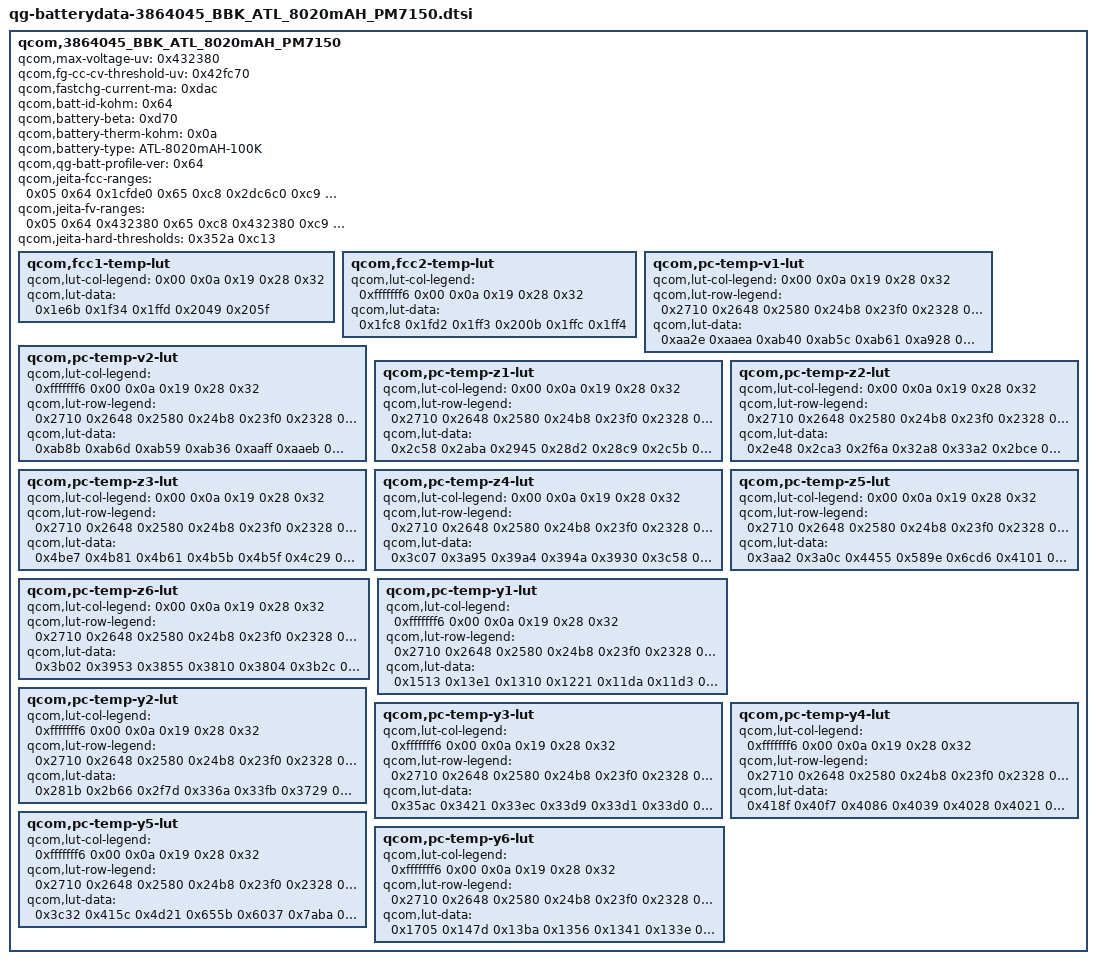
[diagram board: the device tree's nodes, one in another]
 /*
 * Copyright (c) 2026 XiKoTaSu <3329989998@qq.com>
 */			
			
			qcom,3864045_BBK_ATL_8020mAH_PM7150 {
				qcom,max-voltage-uv = <0x432380>;
				qcom,fg-cc-cv-threshold-uv = <0x42fc70>;
				qcom,fastchg-current-ma = <0xdac>;
				qcom,batt-id-kohm = <0x64>;
				qcom,battery-beta = <0xd70>;
				qcom,battery-therm-kohm = <0x0a>;
				qcom,battery-type = "ATL-8020mAH-100K";
				qcom,qg-batt-profile-ver = <0x64>;
				qcom,jeita-fcc-ranges = <0x05 0x64 0x1cfde0 0x65 0xc8 0x2dc6c0 0xc9 0x1c2 0x3567e0 0x1c3 0x221 0x2625a0>;
				qcom,jeita-fv-ranges = <0x05 0x64 0x432380 0x65 0xc8 0x432380 0xc9 0x1c2 0x432380 0x1c3 0x221 0x3e8fa0>;
				qcom,jeita-hard-thresholds = <0x352a 0xc13>;

				qcom,fcc1-temp-lut {
					qcom,lut-col-legend = <0x00 0x0a 0x19 0x28 0x32>;
					qcom,lut-data = <0x1e6b 0x1f34 0x1ffd 0x2049 0x205f>;
				};

				qcom,fcc2-temp-lut {
					qcom,lut-col-legend = <0xfffffff6 0x00 0x0a 0x19 0x28 0x32>;
					qcom,lut-data = <0x1fc8 0x1fd2 0x1ff3 0x200b 0x1ffc 0x1ff4>;
				};

				qcom,pc-temp-v1-lut {
					qcom,lut-col-legend = <0x00 0x0a 0x19 0x28 0x32>;
					qcom,lut-row-legend = <0x2710 0x2648 0x2580 0x24b8 0x23f0 0x2328 0x2260 0x2198 0x20d0 0x2008 0x1f40 0x1e78 0x1db0 0x1ce8 0x1c20 0x1b58 0x1a90 0x19c8 0x1900 0x1838 0x1770 0x16a8 0x15e0 0x1518 0x1450 0x1388 0x12c0 0x11f8 0x1130 0x1068 0xfa0 0xed8 0xe10 0xd48 0xc80 0xbb8 0xaf0 0xa28 0x960 0x898 0x7d0 0x708 0x640 0x578 0x4b0 0x3e8 0x384 0x320 0x2bc 0x258 0x1f4 0x190 0x12c 0xc8 0x64 0x00>;
					qcom,lut-data = <0xaa2e 0xaaea 0xab40 0xab5c 0xab61 0xa928 0xa9f7 0xaa82 0xaa9c 0xaa9e 0xa832 0xa907 0xa9a4 0xa9d1 0xa9d6 0xa748 0xa818 0xa8b7 0xa8f1 0xa8ff 0xa662 0xa72c 0xa7ca 0xa80a 0xa820 0xa580 0xa641 0xa6db 0xa71f 0xa739 0xa4a2 0xa55a 0xa5ed 0xa631 0xa64d 0xa3cb 0xa477 0xa502 0xa545 0xa561 0xa2fa 0xa39a 0xa41a 0xa45c 0xa476 0xa231 0xa2c2 0xa335 0xa374 0xa38c 0xa17b 0xa1f2 0xa253 0xa28d 0xa2a5 0xa0c7 0xa134 0xa17a 0xa1aa 0xa1c1 0x9ff3 0xa07b 0xa0b3 0xa0cf 0xa0e3 0x9ef6 0x9faa 0x9ff1 0x9ffd 0xa00c 0x9dfb 0x9ebc 0x9f15 0x9f2c 0x9f3a 0x9d0f 0x9dd2 0x9e20 0x9e5b 0x9e6d 0x9c31 0x9cec 0x9d46 0x9d92 0x9da8 0x9b8b 0x9c1b 0x9c95 0x9cdd 0x9cf1 0x9b11 0x9b80 0x9bf2 0x9c30 0x9c43 0x9aa1 0x9b10 0x9b4d 0x9b79 0x9b8c 0x9a27 0x9a8f 0x9aaa 0x9ab8 0x9acb 0x99ad 0x99cb 0x99ed 0x99f2 0x9a04 0x992f 0x98ec 0x98f3 0x991b 0x992f 0x98ae 0x9831 0x9814 0x984d 0x985d 0x982d 0x9784 0x9792 0x97b2 0x97be 0x97ae 0x9701 0x9731 0x9738 0x9741 0x972e 0x96ad 0x96d0 0x96c9 0x96cf 0x96be 0x966d 0x966e 0x9662 0x9664 0x965c 0x9632 0x9615 0x9605 0x9601 0x9607 0x95fd 0x95ca 0x95ae 0x95a7 0x95ce 0x95cc 0x9587 0x955f 0x9555 0x95a6 0x959e 0x954c 0x9519 0x950b 0x9584 0x9573 0x9519 0x94dc 0x94c9 0x9567 0x954b 0x94e9 0x94a4 0x948b 0x954d 0x9526 0x94c0 0x9474 0x9452 0x952f 0x9500 0x9498 0x9447 0x941c 0x950f 0x94da 0x946f 0x9414 0x93de 0x94e8 0x94b0 0x9445 0x93da 0x939a 0x94ae 0x9470 0x940d 0x9395 0x934d 0x945d 0x940e 0x93b1 0x9340 0x92f7 0x93fb 0x939e 0x9340 0x92dc 0x9294 0x937e 0x932a 0x92cb 0x926a 0x9224 0x92f0 0x92a6 0x9248 0x91e6 0x91a0 0x9251 0x9208 0x91ad 0x914e 0x910e 0x91cf 0x9181 0x9125 0x90c9 0x908b 0x9178 0x9131 0x90d3 0x907c 0x903d 0x915c 0x9112 0x90be 0x9065 0x9029 0x913e 0x90fe 0x90ac 0x9057 0x901b 0x9122 0x90e6 0x9098 0x9045 0x9008 0x90e3 0x90ab 0x9056 0x8ff2 0x8fa6 0x8fd6 0x8f94 0x8f3b 0x8eca 0x8e76 0x8e1a 0x8de0 0x8d89 0x8d13 0x8cbd 0x8be4 0x8baa 0x8b54 0x8ada 0x8a83 0x88e5 0x88a6 0x8850 0x87d1 0x877d 0x842e 0x83f2 0x83a6 0x8323 0x82d3 0x7530 0x7530 0x7530 0x7530 0x7530>;
				};

				qcom,pc-temp-v2-lut {
					qcom,lut-col-legend = <0xfffffff6 0x00 0x0a 0x19 0x28 0x32>;
					qcom,lut-row-legend = <0x2710 0x2648 0x2580 0x24b8 0x23f0 0x2328 0x2260 0x2198 0x20d0 0x2008 0x1f40 0x1e78 0x1db0 0x1ce8 0x1c20 0x1b58 0x1a90 0x19c8 0x1900 0x1838 0x1770 0x16a8 0x15e0 0x1518 0x1450 0x1388 0x12c0 0x11f8 0x1130 0x1068 0xfa0 0xed8 0xe10 0xd48 0xc80 0xbb8 0xaf0 0xa28 0x960 0x898 0x7d0 0x708 0x640 0x578 0x4b0 0x3e8 0x384 0x320 0x2bc 0x258 0x1f4 0x190 0x12c 0xc8 0x64 0x00>;
					qcom,lut-data = <0xab8b 0xab6d 0xab59 0xab36 0xaaff 0xaaeb 0xaa06 0xaa27 0xaa48 0xaa3e 0xaa12 0xaa04 0xa89c 0xa8f5 0xa93f 0xa94a 0xa926 0xa91c 0xa74d 0xa7da 0xa840 0xa858 0xa83a 0xa833 0xa613 0xa6d5 0xa749 0xa769 0xa74e 0xa749 0xa500 0xa5d6 0xa656 0xa67a 0xa662 0xa65f 0xa422 0xa4d8 0xa566 0xa58d 0xa576 0xa574 0xa351 0xa3e2 0xa479 0xa4a1 0xa48a 0xa488 0xa250 0xa2f4 0xa393 0xa3ba 0xa3a3 0xa3a1 0xa126 0xa20e 0xa2b3 0xa2d6 0xa2bd 0xa2bb 0xa059 0xa13c 0xa1d5 0xa1f3 0xa1db 0xa1d9 0x9fff 0xa08e 0xa0f8 0xa10e 0xa0fb 0xa0fb 0x9fa1 0x9fdc 0xa023 0xa034 0xa021 0xa021 0x9e6b 0x9ef9 0x9f6e 0x9f7a 0x9f54 0x9f4f 0x9c0e 0x9dec 0x9ec8 0x9ece 0x9e8d 0x9e82 0x9a8c 0x9cd6 0x9df0 0x9dfe 0x9dc5 0x9dbc 0x99e3 0x9ba9 0x9cb6 0x9cec 0x9cf7 0x9cfc 0x9956 0x9a95 0x9b87 0x9bf5 0x9c31 0x9c42 0x98aa 0x99cd 0x9aaf 0x9b54 0x9b83 0x9b91 0x97f6 0x9926 0x99f7 0x9ac8 0x9adb 0x9ae2 0x9749 0x987d 0x9941 0x9a09 0x9a0f 0x9a13 0x969a 0x97cd 0x988b 0x9906 0x990c 0x9912 0x9607 0x972b 0x97e6 0x9826 0x982c 0x9833 0x95a2 0x969d 0x9755 0x9788 0x9790 0x9797 0x9553 0x961d 0x96d1 0x9702 0x970e 0x9716 0x950f 0x95a3 0x965a 0x968a 0x9697 0x969e 0x94d6 0x952c 0x95ee 0x961f 0x962b 0x9630 0x94a3 0x94cd 0x958a 0x95bd 0x95c8 0x95cc 0x9474 0x948b 0x952f 0x9563 0x956c 0x956e 0x9449 0x9457 0x94da 0x9510 0x9517 0x9517 0x941e 0x9428 0x948b 0x94c4 0x94cb 0x94c9 0x93f3 0x93fe 0x9440 0x947c 0x9484 0x9481 0x93c7 0x93d5 0x9400 0x9436 0x9440 0x943c 0x9398 0x93af 0x93c9 0x93f4 0x9403 0x93fe 0x9368 0x9388 0x9398 0x93b2 0x93c2 0x93bb 0x9334 0x935b 0x9369 0x936c 0x9367 0x9355 0x92fc 0x9329 0x933c 0x9326 0x92fb 0x92d2 0x92be 0x92f0 0x9308 0x92df 0x929b 0x9264 0x9275 0x92ac 0x92cd 0x9299 0x9247 0x920b 0x9226 0x925e 0x9289 0x924f 0x91f6 0x91b8 0x91d1 0x9204 0x9239 0x9200 0x91a7 0x9167 0x9174 0x919c 0x91d9 0x91a7 0x9153 0x9111 0x911c 0x912b 0x9166 0x913b 0x90e9 0x90a7 0x90c5 0x90b9 0x90dc 0x90b0 0x9061 0x901f 0x9074 0x904d 0x9066 0x9037 0x8ff2 0x8fb8 0x901c 0x8fe5 0x901e 0x9016 0x8fda 0x8fa1 0x8fe9 0x8fb2 0x9009 0x9007 0x8fcb 0x8f93 0x8fb5 0x8f78 0x8ff0 0x8ff1 0x8fb5 0x8f7d 0x8f6b 0x8f32 0x8fc3 0x8fc9 0x8f8b 0x8f4f 0x8eef 0x8ec5 0x8f57 0x8f5b 0x8f0f 0x8ebd 0x8e02 0x8de4 0x8e4d 0x8e1c 0x8daf 0x8d52 0x8c89 0x8c62 0x8c7a 0x8c2b 0x8bc0 0x8b61 0x8a58 0x8a31 0x8a04 0x89b2 0x893c 0x88da 0x872f 0x8706 0x86ad 0x863b 0x85b1 0x853d 0x81f5 0x81e8 0x8178 0x80af 0x801d 0x7fa1 0x719c 0x7000 0x6ede 0x6f3b 0x6fc7 0x7099>;
				};

				qcom,pc-temp-z1-lut {
					qcom,lut-col-legend = <0x00 0x0a 0x19 0x28 0x32>;
					qcom,lut-row-legend = <0x2710 0x2648 0x2580 0x24b8 0x23f0 0x2328 0x2260 0x2198 0x20d0 0x2008 0x1f40 0x1e78 0x1db0 0x1ce8 0x1c20 0x1b58 0x1a90 0x19c8 0x1900 0x1838 0x1770 0x16a8 0x15e0 0x1518 0x1450 0x1388 0x12c0 0x11f8 0x1130 0x1068 0xfa0 0xed8 0xe10 0xd48 0xc80 0xbb8 0xaf0 0xa28 0x960 0x898 0x7d0 0x708 0x640 0x578 0x4b0 0x3e8 0x384 0x320 0x2bc 0x258 0x1f4 0x190 0x12c 0xc8 0x64 0x00>;
					qcom,lut-data = <0x2c58 0x2aba 0x2945 0x28d2 0x28c9 0x2c5b 0x2abf 0x2950 0x28de 0x28d9 0x2c5d 0x2ac0 0x294f 0x28e0 0x28db 0x2c60 0x2abe 0x2949 0x28e0 0x28dd 0x2c60 0x2ab5 0x2945 0x28e1 0x28e0 0x2c5e 0x2aab 0x2942 0x28e3 0x28e4 0x2c5b 0x2aa6 0x2940 0x28e6 0x28e9 0x2c54 0x2aa2 0x2940 0x28e7 0x28ea 0x2c41 0x2a9d 0x2940 0x28e8 0x28e9 0x2c35 0x2a95 0x2940 0x28e8 0x28e9 0x2c35 0x2a90 0x293e 0x28e7 0x28e9 0x2c36 0x2a93 0x293e 0x28e6 0x28e9 0x2c33 0x2a97 0x293f 0x28e6 0x28e9 0x2c2a 0x2a95 0x2940 0x28e6 0x28e9 0x2c21 0x2a85 0x293e 0x28e6 0x28e9 0x2c18 0x2a7b 0x2939 0x28e6 0x28ea 0x2c0f 0x2a7e 0x2937 0x28e6 0x28ea 0x2c0e 0x2a84 0x2939 0x28e6 0x28ea 0x2c1b 0x2a86 0x293c 0x28e7 0x28eb 0x2c28 0x2a89 0x293e 0x28e8 0x28eb 0x2c2a 0x2a8b 0x2941 0x28e9 0x28ec 0x2c27 0x2a8d 0x2943 0x28ea 0x28ed 0x2c28 0x2a8f 0x2946 0x28eb 0x28ee 0x2c2e 0x2a92 0x2948 0x28ed 0x28ef 0x2c33 0x2a95 0x294a 0x28ee 0x28f0 0x2c36 0x2a99 0x294c 0x28ef 0x28f1 0x2c3b 0x2a9e 0x294e 0x28f1 0x28f2 0x2c3f 0x2aa3 0x2951 0x28f2 0x28f3 0x2c42 0x2aa6 0x2954 0x28f4 0x28f4 0x2c46 0x2aa7 0x2956 0x28f5 0x28f5 0x2c47 0x2aa9 0x2959 0x28f7 0x28f6 0x2c4b 0x2aad 0x295b 0x28f8 0x28f7 0x2c50 0x2ab5 0x295d 0x28fa 0x28f8 0x2c54 0x2aba 0x295e 0x28fc 0x28f9 0x2c58 0x2abe 0x2961 0x28fd 0x28fa 0x2c5b 0x2ac0 0x2964 0x28fe 0x28fb 0x2c5d 0x2ac3 0x2966 0x28ff 0x28fc 0x2c5f 0x2ac7 0x2969 0x2901 0x28fe 0x2c62 0x2acd 0x296b 0x2902 0x28ff 0x2c68 0x2ad8 0x296f 0x2904 0x2900 0x2c6f 0x2adf 0x2973 0x2905 0x2902 0x2c82 0x2adb 0x2975 0x2907 0x2903 0x2c8c 0x2ad7 0x2977 0x2909 0x2904 0x2c8a 0x2add 0x297b 0x290a 0x2905 0x2c93 0x2ae1 0x297f 0x290c 0x2906 0x2c7a 0x2ae3 0x2981 0x290d 0x2907 0x2c79 0x2aee 0x2984 0x290e 0x2907 0x2c89 0x2ae2 0x2981 0x290f 0x2908 0x2c8b 0x2af4 0x2984 0x2910 0x2909 0x2c91 0x2aec 0x298b 0x2911 0x290a 0x2c8d 0x2af5 0x298d 0x2914 0x290c 0x2c9b 0x2b16 0x2993 0x2918 0x2910 0x2ca2 0x2b1b 0x299d 0x291d 0x2914 0x2cd0 0x2b33 0x29a8 0x2925 0x291a 0x2cd0 0x2b33 0x29a8 0x2925 0x291a 0x2cd0 0x2b33 0x29a8 0x2925 0x291a>;
				};

				qcom,pc-temp-z2-lut {
					qcom,lut-col-legend = <0x00 0x0a 0x19 0x28 0x32>;
					qcom,lut-row-legend = <0x2710 0x2648 0x2580 0x24b8 0x23f0 0x2328 0x2260 0x2198 0x20d0 0x2008 0x1f40 0x1e78 0x1db0 0x1ce8 0x1c20 0x1b58 0x1a90 0x19c8 0x1900 0x1838 0x1770 0x16a8 0x15e0 0x1518 0x1450 0x1388 0x12c0 0x11f8 0x1130 0x1068 0xfa0 0xed8 0xe10 0xd48 0xc80 0xbb8 0xaf0 0xa28 0x960 0x898 0x7d0 0x708 0x640 0x578 0x4b0 0x3e8 0x384 0x320 0x2bc 0x258 0x1f4 0x190 0x12c 0xc8 0x64 0x00>;
					qcom,lut-data = <0x2e48 0x2ca3 0x2f6a 0x32a8 0x33a2 0x2bce 0x2d32 0x2ed6 0x3249 0x3271 0x2bf3 0x2d89 0x2fa9 0x30e0 0x3203 0x2c42 0x2d8b 0x2fe3 0x3153 0x31c9 0x2c81 0x2d44 0x2fe6 0x31c6 0x3190 0x2cba 0x2cfe 0x2fae 0x31db 0x3174 0x2ce7 0x2ccb 0x2f83 0x31e8 0x315f 0x2cf5 0x2ca5 0x2f8e 0x31c6 0x316a 0x2cfc 0x2ca1 0x2fa6 0x3133 0x31c0 0x2cfb 0x2cad 0x2faf 0x30e6 0x31fe 0x2ce6 0x2cbd 0x2fab 0x30ed 0x31f0 0x2cc2 0x2ccc 0x2faa 0x30f5 0x31d9 0x2c9b 0x2ce3 0x2fc4 0x30f7 0x31df 0x2c64 0x2d8d 0x2fe7 0x3102 0x3210 0x2c45 0x2ffd 0x2fe6 0x310c 0x3240 0x2cda 0x3171 0x2fd2 0x312d 0x325d 0x2deb 0x300c 0x2fc9 0x3148 0x3279 0x2e19 0x2dfd 0x2fd4 0x3159 0x32a5 0x2cfd 0x2dab 0x2fe6 0x3175 0x32da 0x2bff 0x2df1 0x2ffd 0x3174 0x32e1 0x2bed 0x2e2b 0x3020 0x313f 0x32ac 0x2bec 0x2e42 0x3024 0x311c 0x3283 0x2bef 0x2e52 0x2fca 0x315a 0x32aa 0x2bfa 0x2e4c 0x2f7c 0x31bd 0x32f9 0x2c0c 0x2e1f 0x2fc8 0x31d4 0x32da 0x2c25 0x2e02 0x3068 0x31d6 0x31c6 0x2c4c 0x2e1a 0x308b 0x31ca 0x3110 0x2c70 0x2e41 0x3056 0x3137 0x3101 0x2c8d 0x2e4d 0x3020 0x3097 0x3100 0x2ca5 0x2e4b 0x2ffc 0x3069 0x310b 0x2cb5 0x2e49 0x2fe2 0x304d 0x3127 0x2cc0 0x2e4b 0x2fe7 0x3053 0x3140 0x2cc9 0x2e50 0x301f 0x3083 0x3175 0x2cd0 0x2e5b 0x3062 0x30c6 0x31c0 0x2cd6 0x2e74 0x30ae 0x3114 0x3226 0x2ce6 0x2e90 0x30f8 0x3176 0x32a3 0x2d1b 0x2eac 0x3123 0x31e0 0x32fd 0x2d4b 0x2eca 0x3141 0x3262 0x3340 0x2d5a 0x2ee8 0x3167 0x32b8 0x3380 0x2d62 0x2f0a 0x31af 0x32e5 0x33d6 0x2d6f 0x2f1c 0x31e7 0x3301 0x341b 0x2d8d 0x2f13 0x31d3 0x3303 0x341d 0x2da0 0x2f0c 0x31aa 0x3301 0x3405 0x2da6 0x2f0f 0x31bf 0x32e3 0x33cd 0x2ec8 0x2f4f 0x31c7 0x32e1 0x3379 0x2f8e 0x2ffd 0x3190 0x3313 0x3373 0x2e2c 0x3007 0x3141 0x32f8 0x33ad 0x2e2b 0x3053 0x312f 0x3323 0x33e4 0x2de8 0x3087 0x312f 0x338c 0x3478 0x2df6 0x3178 0x3215 0x34d9 0x3412 0x2e06 0x30d8 0x3275 0x33ab 0x3289 0x2d5c 0x308f 0x323d 0x32c0 0x31cd 0x2bc6 0x2fb9 0x3201 0x3208 0x30fa 0x2a6a 0x2e61 0x30e2 0x3122 0x309b 0x2a6a 0x2e61 0x30e2 0x3122 0x309b 0x2a6a 0x2e61 0x30e2 0x3122 0x309b>;
				};

				qcom,pc-temp-z3-lut {
					qcom,lut-col-legend = <0x00 0x0a 0x19 0x28 0x32>;
					qcom,lut-row-legend = <0x2710 0x2648 0x2580 0x24b8 0x23f0 0x2328 0x2260 0x2198 0x20d0 0x2008 0x1f40 0x1e78 0x1db0 0x1ce8 0x1c20 0x1b58 0x1a90 0x19c8 0x1900 0x1838 0x1770 0x16a8 0x15e0 0x1518 0x1450 0x1388 0x12c0 0x11f8 0x1130 0x1068 0xfa0 0xed8 0xe10 0xd48 0xc80 0xbb8 0xaf0 0xa28 0x960 0x898 0x7d0 0x708 0x640 0x578 0x4b0 0x3e8 0x384 0x320 0x2bc 0x258 0x1f4 0x190 0x12c 0xc8 0x64 0x00>;
					qcom,lut-data = <0x4be7 0x4b81 0x4b61 0x4b5b 0x4b5f 0x4c29 0x4bb6 0x4b75 0x4b5c 0x4b55 0x4c3a 0x4bda 0x4b85 0x4b63 0x4b5c 0x4c44 0x4be5 0x4b8e 0x4b69 0x4b5e 0x4c46 0x4bea 0x4b90 0x4b6d 0x4b5f 0x4c36 0x4bec 0x4b91 0x4b6e 0x4b60 0x4c20 0x4beb 0x4b92 0x4b6e 0x4b61 0x4c13 0x4be8 0x4b8e 0x4b6d 0x4b60 0x4c09 0x4be5 0x4b88 0x4b68 0x4b5e 0x4c05 0x4bdf 0x4b85 0x4b64 0x4b5d 0x4c04 0x4bda 0x4b83 0x4b63 0x4b5d 0x4c04 0x4bd6 0x4b82 0x4b63 0x4b5c 0x4c07 0x4bd1 0x4b82 0x4b61 0x4b5b 0x4c0f 0x4bd1 0x4b82 0x4b5e 0x4b58 0x4c1a 0x4bd6 0x4b81 0x4b5c 0x4b57 0x4c2c 0x4bd8 0x4b7e 0x4b5c 0x4b56 0x4c40 0x4bcf 0x4b7c 0x4b5c 0x4b56 0x4c41 0x4bbf 0x4b79 0x4b5b 0x4b54 0x4c1c 0x4bb5 0x4b76 0x4b5b 0x4b51 0x4bfb 0x4bad 0x4b77 0x4b5b 0x4b50 0x4bfa 0x4baa 0x4b7a 0x4b5f 0x4b52 0x4bfb 0x4bb3 0x4b7b 0x4b61 0x4b55 0x4bfd 0x4bc1 0x4b7b 0x4b61 0x4b59 0x4c04 0x4bc3 0x4b7a 0x4b60 0x4b5e 0x4c0c 0x4bc2 0x4b7a 0x4b62 0x4b5f 0x4c12 0x4bc1 0x4b7a 0x4b69 0x4b60 0x4c17 0x4bc0 0x4b7c 0x4b6c 0x4b60 0x4c1a 0x4bbf 0x4b84 0x4b6b 0x4b60 0x4c1b 0x4bbe 0x4b8a 0x4b69 0x4b5f 0x4c1b 0x4bbc 0x4b89 0x4b67 0x4b5e 0x4c19 0x4bbb 0x4b86 0x4b66 0x4b5c 0x4c14 0x4bbb 0x4b84 0x4b65 0x4b5a 0x4c0e 0x4bbb 0x4b82 0x4b64 0x4b58 0x4c08 0x4bba 0x4b80 0x4b62 0x4b57 0x4c02 0x4bb9 0x4b7e 0x4b60 0x4b56 0x4bfa 0x4bb7 0x4b7d 0x4b5f 0x4b56 0x4bee 0x4bb5 0x4b7b 0x4b5f 0x4b55 0x4be6 0x4bb2 0x4b7a 0x4b5f 0x4b55 0x4be5 0x4bb1 0x4b78 0x4b5f 0x4b55 0x4be5 0x4bb0 0x4b77 0x4b5e 0x4b55 0x4be4 0x4baf 0x4b77 0x4b5c 0x4b56 0x4be0 0x4bad 0x4b75 0x4b5c 0x4b56 0x4bde 0x4baa 0x4b73 0x4b5b 0x4b55 0x4bde 0x4ba9 0x4b73 0x4b5c 0x4b55 0x4bbf 0x4ba2 0x4b72 0x4b5b 0x4b54 0x4b92 0x4b8d 0x4b6e 0x4b57 0x4b53 0x4b6b 0x4b8d 0x4b69 0x4b58 0x4b51 0x4b69 0x4b86 0x4b66 0x4b55 0x4b4f 0x4b61 0x4b80 0x4b66 0x4b52 0x4b4d 0x4b5b 0x4b70 0x4b64 0x4b50 0x4b50 0x4b6e 0x4b83 0x4b60 0x4b52 0x4b54 0x4b6f 0x4b7e 0x4b5e 0x4b55 0x4b56 0x4b6f 0x4b6a 0x4b5c 0x4b56 0x4b59 0x4b72 0x4b6d 0x4b5f 0x4b59 0x4b57 0x4b72 0x4b6d 0x4b5f 0x4b59 0x4b57 0x4b72 0x4b6d 0x4b5f 0x4b59 0x4b57>;
				};

				qcom,pc-temp-z4-lut {
					qcom,lut-col-legend = <0x00 0x0a 0x19 0x28 0x32>;
					qcom,lut-row-legend = <0x2710 0x2648 0x2580 0x24b8 0x23f0 0x2328 0x2260 0x2198 0x20d0 0x2008 0x1f40 0x1e78 0x1db0 0x1ce8 0x1c20 0x1b58 0x1a90 0x19c8 0x1900 0x1838 0x1770 0x16a8 0x15e0 0x1518 0x1450 0x1388 0x12c0 0x11f8 0x1130 0x1068 0xfa0 0xed8 0xe10 0xd48 0xc80 0xbb8 0xaf0 0xa28 0x960 0x898 0x7d0 0x708 0x640 0x578 0x4b0 0x3e8 0x384 0x320 0x2bc 0x258 0x1f4 0x190 0x12c 0xc8 0x64 0x00>;
					qcom,lut-data = <0x3c07 0x3a95 0x39a4 0x394a 0x3930 0x3c58 0x3a8b 0x39cb 0x3965 0x3950 0x3c34 0x3a77 0x39c8 0x3977 0x395e 0x3bc1 0x3a56 0x39a9 0x396b 0x3957 0x3b64 0x3a1a 0x398e 0x395b 0x394d 0x3b29 0x39e5 0x3978 0x394f 0x3944 0x3af7 0x39c2 0x3966 0x3943 0x393a 0x3ac9 0x39a6 0x395a 0x393d 0x3934 0x3a9e 0x398f 0x3950 0x393a 0x3930 0x3a77 0x3979 0x3949 0x3936 0x392d 0x3a54 0x396a 0x3944 0x3932 0x3929 0x3a33 0x3963 0x3940 0x392d 0x3925 0x3a10 0x395e 0x393c 0x392b 0x3922 0x39ed 0x3954 0x3939 0x3929 0x3920 0x39c9 0x3942 0x3937 0x3927 0x391e 0x399e 0x3938 0x3936 0x3924 0x391a 0x3974 0x3941 0x3934 0x3920 0x3917 0x396c 0x394c 0x392d 0x391b 0x3915 0x3981 0x394d 0x3927 0x3917 0x3914 0x3993 0x3945 0x3927 0x3917 0x3914 0x3990 0x3941 0x392a 0x3920 0x391c 0x3984 0x394f 0x3932 0x392d 0x3928 0x397a 0x3967 0x3960 0x3944 0x3936 0x3971 0x397c 0x3986 0x395c 0x3945 0x396a 0x3994 0x3981 0x395a 0x3945 0x396c 0x39a0 0x3970 0x3949 0x393c 0x3972 0x3998 0x3961 0x393b 0x3934 0x3978 0x3988 0x394f 0x3935 0x392e 0x397d 0x397b 0x3943 0x3930 0x3929 0x3983 0x3970 0x393e 0x392c 0x3925 0x3982 0x3965 0x393a 0x3928 0x3921 0x397d 0x395c 0x3938 0x3925 0x391e 0x3976 0x3953 0x3936 0x3923 0x391b 0x3970 0x394c 0x3934 0x3922 0x391a 0x396a 0x3947 0x3934 0x3922 0x391a 0x3967 0x3943 0x3933 0x3924 0x391d 0x3965 0x3940 0x3933 0x3926 0x3920 0x3964 0x393e 0x3933 0x392a 0x3926 0x3960 0x393f 0x3933 0x392c 0x3929 0x395a 0x3943 0x3935 0x392d 0x3928 0x3959 0x3946 0x3938 0x392d 0x3926 0x395b 0x3943 0x3936 0x392b 0x3923 0x395b 0x393f 0x3932 0x3928 0x3921 0x3956 0x393e 0x3932 0x3929 0x3922 0x3957 0x3937 0x392e 0x3928 0x3923 0x3973 0x3937 0x3922 0x391f 0x391a 0x399a 0x3933 0x391f 0x3919 0x3916 0x399a 0x3933 0x391b 0x3913 0x3910 0x399f 0x3936 0x3915 0x390f 0x390b 0x399f 0x3945 0x391a 0x3917 0x390e 0x3992 0x393d 0x3929 0x391c 0x3910 0x39a0 0x3949 0x392d 0x391b 0x390f 0x39ac 0x3964 0x392f 0x391a 0x390d 0x39b7 0x3967 0x392f 0x3918 0x3910 0x39b7 0x3967 0x392f 0x3918 0x3910 0x39b7 0x3967 0x392f 0x3918 0x3910>;
				};

				qcom,pc-temp-z5-lut {
					qcom,lut-col-legend = <0x00 0x0a 0x19 0x28 0x32>;
					qcom,lut-row-legend = <0x2710 0x2648 0x2580 0x24b8 0x23f0 0x2328 0x2260 0x2198 0x20d0 0x2008 0x1f40 0x1e78 0x1db0 0x1ce8 0x1c20 0x1b58 0x1a90 0x19c8 0x1900 0x1838 0x1770 0x16a8 0x15e0 0x1518 0x1450 0x1388 0x12c0 0x11f8 0x1130 0x1068 0xfa0 0xed8 0xe10 0xd48 0xc80 0xbb8 0xaf0 0xa28 0x960 0x898 0x7d0 0x708 0x640 0x578 0x4b0 0x3e8 0x384 0x320 0x2bc 0x258 0x1f4 0x190 0x12c 0xc8 0x64 0x00>;
					qcom,lut-data = <0x3aa2 0x3a0c 0x4455 0x589e 0x6cd6 0x4101 0x466c 0x50c4 0x5f1f 0x66d3 0x440b 0x5033 0x5a81 0x63c9 0x6e46 0x4627 0x5695 0x61bc 0x6b71 0x709f 0x4700 0x5b5a 0x6772 0x7350 0x724e 0x46fc 0x5fa2 0x6cff 0x78c5 0x770d 0x46d5 0x63de 0x7023 0x7cb9 0x7c8f 0x4709 0x67d7 0x7079 0x7c03 0x7e42 0x478f 0x6c22 0x70a4 0x75f5 0x7f43 0x484c 0x7444 0x7170 0x72aa 0x813f 0x4958 0x7b62 0x7435 0x761c 0x86ac 0x4b00 0x7ec4 0x77f8 0x7a62 0x8c79 0x4e15 0x82b7 0x7eff 0x78c0 0x8b67 0x5508 0x8b23 0x8694 0x728a 0x843c 0x5e4c 0x9d7c 0x875d 0x7045 0x811d 0x6f07 0xa76c 0x82f1 0x7306 0x8875 0x8381 0x9af2 0x8163 0x77f3 0x9073 0x865b 0x88d2 0x85a8 0x8049 0x8d15 0x6eb3 0x83a1 0x8d0e 0x8d87 0x8314 0x59de 0x818d 0x9e9d 0x9ed1 0x81ac 0x5aff 0x81a4 0xbfba 0xbb12 0x90ba 0x61e3 0xc09b 0xc9b4 0xca7f 0x9bfb 0x6b65 0xffff 0xb4c7 0xa279 0x8a3d 0x7e8f 0xffff 0x9980 0x69b9 0x6d19 0x981a 0xffff 0x8330 0x643f 0x6868 0xb55f 0xe11c 0x6f62 0x6eb1 0x6b26 0xd8a9 0xca01 0x6dfe 0x77a0 0x6ef5 0xed5c 0xb78e 0x83f5 0x7c6a 0x776f 0xf6f3 0xad8c 0x9ac9 0x8157 0x81c7 0xfc7f 0xa6a5 0xa705 0x89af 0x877a 0xf756 0xa3db 0xb1b8 0x959b 0x8b68 0xe463 0xa926 0xbeb5 0xa329 0x917e 0xcf91 0xb426 0xce68 0xb4e7 0x9d75 0xbee8 0xc000 0xdc1c 0xc24c 0xaa22 0xaec9 0xcf16 0xea3c 0xc829 0xb511 0x9e84 0xd8a6 0xf505 0xcbe3 0xbe32 0x8b4d 0xda74 0xf228 0xcb60 0xbc83 0x7f7d 0xda7e 0xe39a 0xc4be 0xa906 0x828f 0xda4f 0xd5a7 0xbb37 0x9bb2 0x8a5d 0xd6ca 0xc836 0xa7c4 0x9a43 0x8cf0 0xd13d 0xbaad 0x9406 0x9942 0x88ee 0xc453 0xae8e 0x8ff2 0x96e7 0x8773 0xb825 0xa48a 0x8e88 0x9304 0x9230 0xb473 0xa043 0x8902 0x85e5 0x793e 0xab55 0xa04a 0x81b0 0x7b5c 0x4e30 0x75ef 0xa0c1 0x7e24 0x8009 0x3c43 0x75d3 0x89b8 0x8c85 0x824e 0x3b98 0x68a5 0x84c9 0x88ec 0x8691 0x3952 0x60a6 0x931d 0x8615 0x8ebd 0x383b 0x5078 0x7e00 0x6838 0x866f 0x3eaa 0x60ac 0x5d3e 0x5c0c 0x7cb9 0x3c80 0x5449 0x5474 0x5e7c 0x872a 0x3a3f 0x41c1 0x4ec9 0x5f7a 0x904f 0x3896 0x40ca 0x50c7 0x65b2 0x7cd7 0x3896 0x40ca 0x50c7 0x65b2 0x7cd7 0x3896 0x40ca 0x50c7 0x65b2 0x7cd7>;
				};

				qcom,pc-temp-z6-lut {
					qcom,lut-col-legend = <0x00 0x0a 0x19 0x28 0x32>;
					qcom,lut-row-legend = <0x2710 0x2648 0x2580 0x24b8 0x23f0 0x2328 0x2260 0x2198 0x20d0 0x2008 0x1f40 0x1e78 0x1db0 0x1ce8 0x1c20 0x1b58 0x1a90 0x19c8 0x1900 0x1838 0x1770 0x16a8 0x15e0 0x1518 0x1450 0x1388 0x12c0 0x11f8 0x1130 0x1068 0xfa0 0xed8 0xe10 0xd48 0xc80 0xbb8 0xaf0 0xa28 0x960 0x898 0x7d0 0x708 0x640 0x578 0x4b0 0x3e8 0x384 0x320 0x2bc 0x258 0x1f4 0x190 0x12c 0xc8 0x64 0x00>;
					qcom,lut-data = <0x3b02 0x3953 0x3855 0x3810 0x3804 0x3b2c 0x395b 0x3870 0x381e 0x3810 0x3b19 0x395d 0x3873 0x3829 0x3819 0x3adb 0x3956 0x386a 0x3827 0x3818 0x3aa1 0x3937 0x3861 0x3823 0x3815 0x3a74 0x3917 0x3858 0x3820 0x3813 0x3a4a 0x3903 0x384f 0x381b 0x3810 0x3a27 0x38f1 0x3847 0x3817 0x380d 0x3a08 0x38e1 0x383f 0x3813 0x380b 0x39ee 0x38d3 0x383a 0x3810 0x3808 0x39d9 0x38c8 0x3837 0x380d 0x3806 0x39c6 0x38c2 0x3835 0x380b 0x3804 0x39b4 0x38be 0x3833 0x3809 0x3802 0x39a2 0x38b8 0x3832 0x3807 0x3800 0x3993 0x38b1 0x3830 0x3805 0x37fe 0x398a 0x38ac 0x382d 0x3803 0x37fc 0x3982 0x38a8 0x382a 0x3801 0x37fb 0x397b 0x38a6 0x3826 0x37ff 0x37f9 0x3975 0x38a2 0x3822 0x37fd 0x37f7 0x3971 0x389c 0x3823 0x37fd 0x37f6 0x396f 0x389a 0x3826 0x3803 0x37fb 0x396d 0x38a4 0x382c 0x380a 0x3802 0x396d 0x38b7 0x383f 0x3815 0x380b 0x396e 0x38c3 0x3850 0x381f 0x3814 0x3970 0x38ce 0x384d 0x381f 0x3815 0x3974 0x38d3 0x3847 0x381c 0x3812 0x397c 0x38d0 0x3843 0x3818 0x380f 0x3983 0x38c9 0x3840 0x3815 0x380c 0x3987 0x38c5 0x383e 0x3812 0x380a 0x398b 0x38c0 0x383c 0x380f 0x3807 0x398b 0x38bc 0x3839 0x380d 0x3805 0x3988 0x38b8 0x3837 0x380b 0x3802 0x3984 0x38b5 0x3835 0x380a 0x3800 0x3980 0x38b3 0x3834 0x3809 0x37ff 0x397c 0x38b1 0x3833 0x3808 0x37ff 0x3977 0x38b0 0x3833 0x3808 0x3800 0x3972 0x38b0 0x3832 0x3808 0x3801 0x396f 0x38af 0x3832 0x380b 0x3803 0x3970 0x38b0 0x3832 0x380c 0x3805 0x3973 0x38b4 0x3833 0x380c 0x3805 0x3975 0x38b6 0x3834 0x380b 0x3804 0x3976 0x38b5 0x3833 0x380b 0x3804 0x3978 0x38b4 0x3832 0x380a 0x3802 0x397b 0x38b6 0x3832 0x380a 0x3803 0x396e 0x38b3 0x3831 0x380a 0x3803 0x3968 0x38aa 0x382b 0x3804 0x37ff 0x3964 0x38ab 0x3827 0x3802 0x37fc 0x3964 0x38a6 0x3824 0x37fe 0x37f8 0x3965 0x38a6 0x3822 0x37fb 0x37f5 0x3963 0x38a6 0x3823 0x37fd 0x37f8 0x396e 0x38b0 0x3829 0x3802 0x37fc 0x397b 0x38b8 0x382b 0x3803 0x37fd 0x3989 0x38be 0x382d 0x3805 0x37ff 0x399e 0x38ca 0x3832 0x3807 0x3800 0x399e 0x38ca 0x3832 0x3807 0x3800 0x399e 0x38ca 0x3832 0x3807 0x3800>;
				};

				qcom,pc-temp-y1-lut {
					qcom,lut-col-legend = <0xfffffff6 0x00 0x0a 0x19 0x28 0x32>;
					qcom,lut-row-legend = <0x2710 0x2648 0x2580 0x24b8 0x23f0 0x2328 0x2260 0x2198 0x20d0 0x2008 0x1f40 0x1e78 0x1db0 0x1ce8 0x1c20 0x1b58 0x1a90 0x19c8 0x1900 0x1838 0x1770 0x16a8 0x15e0 0x1518 0x1450 0x1388 0x12c0 0x11f8 0x1130 0x1068 0xfa0 0xed8 0xe10 0xd48 0xc80 0xbb8 0xaf0 0xa28 0x960 0x898 0x7d0 0x708 0x640 0x578 0x4b0 0x3e8 0x384 0x320 0x2bc 0x258 0x1f4 0x190 0x12c 0xc8 0x64 0x00>;
					qcom,lut-data = <0x1513 0x13e1 0x1310 0x1221 0x11da 0x11d3 0x1521 0x13e5 0x130f 0x1221 0x11da 0x11d2 0x152e 0x13e7 0x130d 0x1221 0x11da 0x11d2 0x1539 0x13e9 0x130b 0x1221 0x11d9 0x11d2 0x1540 0x13e9 0x1309 0x1220 0x11d9 0x11d2 0x1541 0x13e9 0x1307 0x121f 0x11d8 0x11d2 0x153e 0x13e4 0x1304 0x121c 0x11d8 0x11d2 0x1539 0x13de 0x1301 0x1219 0x11d7 0x11d3 0x1536 0x13df 0x12ff 0x1219 0x11d7 0x11d2 0x1533 0x13e3 0x12fc 0x1219 0x11d7 0x11d1 0x1532 0x13e5 0x12fa 0x1218 0x11d7 0x11d1 0x1537 0x13e3 0x12f9 0x1217 0x11d5 0x11d1 0x153c 0x13e1 0x12f8 0x1215 0x11d4 0x11d1 0x153c 0x13e0 0x12f6 0x1214 0x11d4 0x11d1 0x153c 0x13e0 0x12f3 0x1213 0x11d4 0x11d1 0x153c 0x13e0 0x12f3 0x1212 0x11d4 0x11d1 0x153c 0x13e1 0x12f6 0x1213 0x11d4 0x11d1 0x153b 0x13e4 0x12f8 0x1213 0x11d4 0x11d2 0x1538 0x13e7 0x12f7 0x1213 0x11d4 0x11d2 0x1530 0x13eb 0x12f4 0x1214 0x11d5 0x11d2 0x152e 0x13ec 0x12f3 0x1214 0x11d5 0x11d2 0x1534 0x13ed 0x12f2 0x1215 0x11d5 0x11d2 0x1539 0x13ed 0x12f2 0x1215 0x11d4 0x11d2 0x153a 0x13ed 0x12f3 0x1216 0x11d5 0x11d2 0x153a 0x13ed 0x12f5 0x1217 0x11d6 0x11d2 0x1538 0x13ed 0x12f7 0x1217 0x11d7 0x11d2 0x152f 0x13ee 0x12f9 0x1218 0x11d7 0x11d3 0x1529 0x13ee 0x12fb 0x1219 0x11d7 0x11d3 0x1530 0x13f0 0x12fc 0x121c 0x11d8 0x11d4 0x153a 0x13f2 0x12fd 0x121e 0x11d9 0x11d4 0x1538 0x13f3 0x12fe 0x1220 0x11da 0x11d5 0x152d 0x13f4 0x1301 0x1222 0x11db 0x11d6 0x1529 0x13f4 0x1304 0x1224 0x11dc 0x11d7 0x152a 0x13f5 0x1306 0x1225 0x11de 0x11d7 0x152b 0x13f6 0x1308 0x1227 0x11df 0x11d8 0x152e 0x13f9 0x1308 0x122a 0x11e0 0x11d9 0x1530 0x1400 0x1309 0x122d 0x11e1 0x11da 0x1531 0x1402 0x1309 0x122f 0x11e2 0x11db 0x152d 0x13fd 0x130b 0x1231 0x11e3 0x11dc 0x1529 0x13f8 0x130c 0x1232 0x11e4 0x11dc 0x1531 0x13fa 0x1313 0x1234 0x11e5 0x11dd 0x153e 0x13ff 0x1319 0x1236 0x11e6 0x11de 0x1534 0x13f7 0x1315 0x1238 0x11e7 0x11df 0x1529 0x13f2 0x131b 0x123a 0x11e8 0x11de 0x152a 0x13fa 0x131c 0x123b 0x11ea 0x11e0 0x1547 0x1407 0x1320 0x123d 0x11ea 0x11e0 0x1531 0x13fd 0x1329 0x1240 0x11ea 0x11e1 0x154b 0x13f8 0x132b 0x123f 0x11eb 0x11e2 0x1539 0x13fe 0x132c 0x1243 0x11eb 0x11e1 0x152a 0x13fd 0x132a 0x1246 0x11ed 0x11e2 0x1545 0x13fe 0x132c 0x1249 0x11ee 0x11e3 0x154c 0x1402 0x1333 0x1250 0x11f1 0x11e5 0x1547 0x141d 0x1340 0x1259 0x11f4 0x11e7 0x155d 0x1432 0x135b 0x1266 0x11fa 0x11eb 0x155d 0x1432 0x135b 0x1266 0x11fa 0x11eb 0x155d 0x1432 0x135b 0x1266 0x11fa 0x11eb>;
				};

				qcom,pc-temp-y2-lut {
					qcom,lut-col-legend = <0xfffffff6 0x00 0x0a 0x19 0x28 0x32>;
					qcom,lut-row-legend = <0x2710 0x2648 0x2580 0x24b8 0x23f0 0x2328 0x2260 0x2198 0x20d0 0x2008 0x1f40 0x1e78 0x1db0 0x1ce8 0x1c20 0x1b58 0x1a90 0x19c8 0x1900 0x1838 0x1770 0x16a8 0x15e0 0x1518 0x1450 0x1388 0x12c0 0x11f8 0x1130 0x1068 0xfa0 0xed8 0xe10 0xd48 0xc80 0xbb8 0xaf0 0xa28 0x960 0x898 0x7d0 0x708 0x640 0x578 0x4b0 0x3e8 0x384 0x320 0x2bc 0x258 0x1f4 0x190 0x12c 0xc8 0x64 0x00>;
					qcom,lut-data = <0x281b 0x2b66 0x2f7d 0x336a 0x33fb 0x3729 0x27bd 0x2b9a 0x2f59 0x3308 0x3416 0x36a4 0x2795 0x2bce 0x2f33 0x32a6 0x3416 0x35e6 0x2796 0x2bff 0x2f0d 0x3249 0x3402 0x3520 0x27b5 0x2c28 0x2ee8 0x31f9 0x33e0 0x347f 0x27e9 0x2c47 0x2ec2 0x31bf 0x33b4 0x3431 0x28a0 0x2c60 0x2e95 0x3190 0x335c 0x341a 0x2967 0x2c71 0x2e70 0x316e 0x3301 0x340c 0x28f6 0x2c71 0x2e65 0x316a 0x32d6 0x33f6 0x2712 0x2c6b 0x2e5f 0x3175 0x32ac 0x33ce 0x2641 0x2c71 0x2e5f 0x3170 0x329a 0x33ba 0x281b 0x2d5e 0x2e70 0x312c 0x32a3 0x33b4 0x2a2a 0x2e5d 0x2e90 0x30e6 0x32ad 0x33a9 0x296e 0x2e54 0x2ee0 0x30da 0x329a 0x3396 0x26e3 0x2e0f 0x2f6b 0x30eb 0x3271 0x337f 0x25e4 0x2dfa 0x2fb1 0x3114 0x3259 0x337c 0x25e0 0x2e34 0x2fca 0x318f 0x3257 0x339e 0x25de 0x2e79 0x2fdf 0x3208 0x3278 0x33d6 0x25dc 0x2e99 0x2ff5 0x325d 0x336f 0x3446 0x25d9 0x2eb1 0x300d 0x32a4 0x34ea 0x34e4 0x25d8 0x2ec9 0x3037 0x32a4 0x3528 0x351e 0x25d6 0x2eeb 0x3090 0x3265 0x34c3 0x34fb 0x25d5 0x2f15 0x30e3 0x3242 0x347e 0x34e3 0x25d3 0x2f4b 0x3118 0x32a8 0x347c 0x3516 0x25d1 0x2f81 0x3141 0x333d 0x348d 0x3576 0x25ce 0x2f89 0x315d 0x3371 0x34d7 0x3604 0x25cd 0x2f73 0x3177 0x3389 0x3583 0x36f5 0x25cb 0x2f51 0x318a 0x33a5 0x35d7 0x3761 0x25c9 0x2d9f 0x3197 0x33db 0x35b5 0x371f 0x25c7 0x2b6c 0x31a5 0x3410 0x3590 0x36d7 0x25c6 0x2ace 0x31b9 0x3439 0x35b3 0x36f2 0x25c4 0x28fe 0x31d5 0x3468 0x3618 0x376e 0x25c3 0x27bb 0x31dc 0x347c 0x363a 0x37de 0x25c2 0x2735 0x31b2 0x3458 0x3623 0x383c 0x25c2 0x269e 0x317e 0x342f 0x360b 0x3879 0x25c1 0x2678 0x3160 0x3423 0x3614 0x3842 0x25c0 0x262b 0x3140 0x3410 0x362e 0x37b5 0x25c0 0x25f8 0x3112 0x33ff 0x3630 0x3756 0x25c0 0x25e8 0x30c4 0x33db 0x3622 0x36d2 0x25bf 0x25dd 0x3060 0x33b5 0x360f 0x366b 0x25bf 0x25d4 0x2fe6 0x3399 0x35f5 0x368e 0x25bf 0x25cc 0x2f50 0x337f 0x35d5 0x36b6 0x25bf 0x25c6 0x2e87 0x3317 0x3583 0x36b7 0x25bf 0x25c2 0x2db3 0x331f 0x3591 0x36b3 0x25bf 0x25c1 0x2d7c 0x32be 0x34e6 0x3589 0x25be 0x25c0 0x2c4a 0x32a3 0x3517 0x3575 0x25be 0x25bf 0x2c1b 0x3210 0x3508 0x3509 0x25be 0x25be 0x2bea 0x3245 0x3490 0x34d6 0x25be 0x25be 0x2bb0 0x323b 0x3485 0x33fc 0x25be 0x25bd 0x2b7d 0x31e3 0x340f 0x33d3 0x25bd 0x25bd 0x2b28 0x3106 0x33b2 0x332b 0x25bd 0x25bd 0x29c5 0x305b 0x3357 0x32d0 0x25bc 0x25bc 0x26d4 0x2fe9 0x3244 0x32a1 0x25bb 0x25bb 0x25ff 0x2f49 0x3115 0x315c 0x25bb 0x25bb 0x25ff 0x2f49 0x3115 0x315c 0x25bb 0x25bb 0x25ff 0x2f49 0x3115 0x315c>;
				};

				qcom,pc-temp-y3-lut {
					qcom,lut-col-legend = <0xfffffff6 0x00 0x0a 0x19 0x28 0x32>;
					qcom,lut-row-legend = <0x2710 0x2648 0x2580 0x24b8 0x23f0 0x2328 0x2260 0x2198 0x20d0 0x2008 0x1f40 0x1e78 0x1db0 0x1ce8 0x1c20 0x1b58 0x1a90 0x19c8 0x1900 0x1838 0x1770 0x16a8 0x15e0 0x1518 0x1450 0x1388 0x12c0 0x11f8 0x1130 0x1068 0xfa0 0xed8 0xe10 0xd48 0xc80 0xbb8 0xaf0 0xa28 0x960 0x898 0x7d0 0x708 0x640 0x578 0x4b0 0x3e8 0x384 0x320 0x2bc 0x258 0x1f4 0x190 0x12c 0xc8 0x64 0x00>;
					qcom,lut-data = <0x35ac 0x3421 0x33ec 0x33d9 0x33d1 0x33d0 0x3571 0x3425 0x33ee 0x33d8 0x33d1 0x33d0 0x3541 0x3428 0x33f0 0x33d8 0x33d1 0x33d0 0x351d 0x342c 0x33f2 0x33d8 0x33d2 0x33d0 0x3507 0x342f 0x33f4 0x33d7 0x33d2 0x33d1 0x3501 0x3431 0x33f5 0x33d7 0x33d2 0x33d1 0x3511 0x3432 0x33f6 0x33d8 0x33d2 0x33d1 0x3526 0x3434 0x33f7 0x33d8 0x33d3 0x33d1 0x3509 0x3437 0x33f8 0x33d9 0x33d3 0x33d1 0x3499 0x343e 0x33f9 0x33da 0x33d3 0x33d1 0x3466 0x3441 0x33fa 0x33db 0x33d3 0x33d1 0x3467 0x3438 0x33fa 0x33db 0x33d3 0x33d1 0x3469 0x342c 0x33fa 0x33db 0x33d3 0x33d1 0x3466 0x3423 0x33fb 0x33dc 0x33d3 0x33d1 0x345b 0x341b 0x33fd 0x33de 0x33d4 0x33d1 0x3452 0x3416 0x33fd 0x33df 0x33d4 0x33d1 0x344c 0x3412 0x33f8 0x33df 0x33d4 0x33d2 0x3446 0x340f 0x33f2 0x33df 0x33d5 0x33d3 0x3443 0x340c 0x33f0 0x33df 0x33d6 0x33d4 0x343e 0x3409 0x33ee 0x33df 0x33d8 0x33d5 0x3439 0x3405 0x33ec 0x33de 0x33d8 0x33d5 0x3430 0x3402 0x33e9 0x33db 0x33d5 0x33d2 0x342a 0x33ff 0x33e8 0x33d9 0x33d2 0x33d0 0x342d 0x33fd 0x33e6 0x33d7 0x33d2 0x33d0 0x3438 0x33fb 0x33e6 0x33d5 0x33d2 0x33d0 0x3443 0x33f8 0x33e5 0x33d5 0x33d1 0x33d0 0x3450 0x33f3 0x33e4 0x33d5 0x33d1 0x33d0 0x3460 0x33ed 0x33e4 0x33d5 0x33d1 0x33d0 0x3475 0x33e6 0x33e4 0x33d6 0x33d1 0x33d0 0x348e 0x33e0 0x33e5 0x33d7 0x33d1 0x33d0 0x34a9 0x33df 0x33e5 0x33d8 0x33d1 0x33d0 0x34c5 0x33de 0x33e5 0x33d8 0x33d1 0x33d0 0x34e4 0x33dd 0x33e4 0x33d7 0x33d1 0x33d0 0x3504 0x33e5 0x33e4 0x33d7 0x33d2 0x33d0 0x3527 0x33ef 0x33e3 0x33d7 0x33d2 0x33d0 0x3550 0x33f3 0x33e3 0x33d6 0x33d2 0x33d0 0x3580 0x33f6 0x33e4 0x33d5 0x33d1 0x33d0 0x35b1 0x33fa 0x33e4 0x33d5 0x33d1 0x33cf 0x35e4 0x3407 0x33e4 0x33d5 0x33d1 0x33d0 0x3615 0x341b 0x33e5 0x33d5 0x33d1 0x33d0 0x363d 0x3438 0x33e7 0x33d5 0x33d1 0x33d0 0x3662 0x3465 0x33ea 0x33d5 0x33d1 0x33d0 0x3694 0x34a4 0x33ec 0x33d4 0x33d1 0x33d0 0x36c1 0x34fc 0x33ed 0x33d4 0x33d1 0x33d0 0x36c3 0x352b 0x33ed 0x33d6 0x33d1 0x33d0 0x36ea 0x357c 0x33ef 0x33d7 0x33d2 0x33d1 0x370b 0x35c6 0x33f5 0x33d8 0x33d2 0x33d1 0x373b 0x3601 0x33fc 0x33d9 0x33d2 0x33d2 0x3769 0x3634 0x3404 0x33da 0x33d4 0x33d2 0x37a0 0x366d 0x340c 0x33dd 0x33d5 0x33d3 0x37dc 0x368c 0x3411 0x33dc 0x33d4 0x33d3 0x3831 0x36c0 0x3417 0x33dd 0x33d5 0x33d3 0x389f 0x3727 0x342c 0x33e1 0x33d6 0x33d4 0x395f 0x37aa 0x3464 0x33e5 0x33d7 0x33d4 0x395f 0x37aa 0x3464 0x33e5 0x33d7 0x33d4 0x395f 0x37aa 0x3464 0x33e5 0x33d7 0x33d4>;
				};

				qcom,pc-temp-y4-lut {
					qcom,lut-col-legend = <0xfffffff6 0x00 0x0a 0x19 0x28 0x32>;
					qcom,lut-row-legend = <0x2710 0x2648 0x2580 0x24b8 0x23f0 0x2328 0x2260 0x2198 0x20d0 0x2008 0x1f40 0x1e78 0x1db0 0x1ce8 0x1c20 0x1b58 0x1a90 0x19c8 0x1900 0x1838 0x1770 0x16a8 0x15e0 0x1518 0x1450 0x1388 0x12c0 0x11f8 0x1130 0x1068 0xfa0 0xed8 0xe10 0xd48 0xc80 0xbb8 0xaf0 0xa28 0x960 0x898 0x7d0 0x708 0x640 0x578 0x4b0 0x3e8 0x384 0x320 0x2bc 0x258 0x1f4 0x190 0x12c 0xc8 0x64 0x00>;
					qcom,lut-data = <0x418f 0x40f7 0x4086 0x4039 0x4028 0x4021 0x4226 0x410a 0x408a 0x4039 0x4027 0x4021 0x428f 0x412b 0x408f 0x403a 0x4026 0x4020 0x42d1 0x414f 0x4094 0x403b 0x4026 0x4020 0x42f2 0x416d 0x4099 0x403c 0x4026 0x4021 0x42fb 0x4179 0x409b 0x403d 0x4026 0x4021 0x42cf 0x417c 0x409c 0x403e 0x4027 0x4021 0x4296 0x417d 0x409e 0x4040 0x4028 0x4022 0x42ca 0x417a 0x40a1 0x4041 0x4029 0x4023 0x439f 0x416f 0x40a7 0x4042 0x402b 0x4024 0x441c 0x416e 0x40af 0x4044 0x402d 0x4025 0x443b 0x41cc 0x40b7 0x4049 0x4030 0x4027 0x444b 0x4232 0x40c2 0x404f 0x4033 0x402a 0x43ce 0x4235 0x40e6 0x4059 0x4037 0x402d 0x4268 0x4221 0x4125 0x4067 0x403b 0x4030 0x41db 0x41fd 0x4135 0x4070 0x4041 0x4034 0x41d9 0x4183 0x4118 0x4074 0x4046 0x4038 0x41d8 0x4116 0x40f2 0x407a 0x404c 0x403d 0x41c0 0x4107 0x40d2 0x408c 0x405b 0x4048 0x4187 0x4102 0x40b2 0x40a1 0x406d 0x4055 0x4157 0x40f6 0x4096 0x409b 0x406b 0x4055 0x412e 0x40dc 0x407b 0x4062 0x4047 0x403b 0x4114 0x40c1 0x406a 0x403d 0x402d 0x4028 0x410c 0x40b2 0x4062 0x4037 0x4029 0x4025 0x4108 0x40a5 0x405d 0x4034 0x4027 0x4023 0x4107 0x4098 0x405c 0x4034 0x4027 0x4023 0x4109 0x4087 0x405c 0x4035 0x4027 0x4024 0x410b 0x407f 0x405c 0x4036 0x4029 0x4025 0x410d 0x408b 0x405c 0x4038 0x402b 0x4027 0x4111 0x409b 0x405d 0x403b 0x402e 0x4029 0x4115 0x40a0 0x405c 0x403e 0x4031 0x402c 0x411a 0x40ad 0x4058 0x4043 0x4036 0x4030 0x411f 0x40b7 0x4057 0x4045 0x403a 0x4034 0x4126 0x40bb 0x4057 0x4046 0x4040 0x4039 0x412d 0x40c1 0x4058 0x4047 0x4043 0x403c 0x4134 0x40c8 0x405a 0x4043 0x403d 0x4037 0x413c 0x40d6 0x405c 0x403a 0x402e 0x402b 0x4140 0x40e1 0x405f 0x4034 0x4028 0x4025 0x4143 0x40e9 0x4063 0x4031 0x4026 0x4024 0x4144 0x40ef 0x4067 0x402f 0x4026 0x4023 0x4144 0x40f4 0x406d 0x4031 0x4027 0x4024 0x4143 0x40f8 0x4073 0x4035 0x4029 0x4025 0x4146 0x40f7 0x407c 0x4039 0x402a 0x4025 0x414e 0x40fc 0x407d 0x403a 0x4028 0x4023 0x414a 0x4101 0x4073 0x4033 0x4023 0x401f 0x4150 0x411e 0x4084 0x403c 0x402a 0x4025 0x4163 0x4141 0x4096 0x4045 0x4030 0x4029 0x417b 0x416c 0x40b2 0x404e 0x4034 0x402e 0x4194 0x41a2 0x40da 0x405a 0x403c 0x4037 0x41a4 0x41dc 0x410b 0x4063 0x403c 0x4034 0x41a3 0x41f6 0x4114 0x4058 0x402d 0x4026 0x4199 0x41f5 0x4112 0x405b 0x402e 0x4027 0x4196 0x41ec 0x4136 0x406e 0x4035 0x402c 0x41b4 0x41ec 0x417c 0x408c 0x4046 0x4036 0x41b4 0x41ec 0x417c 0x408c 0x4046 0x4036 0x41b4 0x41ec 0x417c 0x408c 0x4046 0x4036>;
				};

				qcom,pc-temp-y5-lut {
					qcom,lut-col-legend = <0xfffffff6 0x00 0x0a 0x19 0x28 0x32>;
					qcom,lut-row-legend = <0x2710 0x2648 0x2580 0x24b8 0x23f0 0x2328 0x2260 0x2198 0x20d0 0x2008 0x1f40 0x1e78 0x1db0 0x1ce8 0x1c20 0x1b58 0x1a90 0x19c8 0x1900 0x1838 0x1770 0x16a8 0x15e0 0x1518 0x1450 0x1388 0x12c0 0x11f8 0x1130 0x1068 0xfa0 0xed8 0xe10 0xd48 0xc80 0xbb8 0xaf0 0xa28 0x960 0x898 0x7d0 0x708 0x640 0x578 0x4b0 0x3e8 0x384 0x320 0x2bc 0x258 0x1f4 0x190 0x12c 0xc8 0x64 0x00>;
					qcom,lut-data = <0x3c32 0x415c 0x4d21 0x655b 0x6037 0x7aba 0x376f 0x43cf 0x51f8 0x61d5 0x62f8 0x78ff 0x3555 0x4794 0x5609 0x5ce3 0x643d 0x7726 0x3563 0x4b9a 0x5922 0x57ac 0x6462 0x7560 0x371a 0x4ecd 0x5b11 0x5358 0x63c2 0x73de 0x3a12 0x501f 0x5ba2 0x510a 0x62b1 0x72ce 0x470d 0x5014 0x5ac9 0x4fbe 0x60b1 0x70bf 0x55b6 0x4ff5 0x595c 0x4edf 0x5e04 0x6dc7 0x5180 0x5214 0x57a1 0x4f74 0x5b5f 0x6ac9 0x3c92 0x58de 0x547e 0x516c 0x5877 0x66f2 0x336c 0x5b81 0x51a0 0x5101 0x55ce 0x62d3 0x45a2 0x4f82 0x4f37 0x4cf9 0x527d 0x5e65 0x59d8 0x4273 0x4d31 0x49aa 0x4f8f 0x59e6 0x541c 0x4795 0x4ba1 0x4990 0x4e07 0x5533 0x3f4f 0x583d 0x4a57 0x49e5 0x4ce9 0x509a 0x3774 0x5e3a 0x4ae5 0x4a44 0x4c85 0x4f01 0x3a6b 0x5be2 0x5441 0x4b3f 0x4c61 0x4fb2 0x3e29 0x59c7 0x5d53 0x4cdf 0x4cdc 0x514f 0x4073 0x5a72 0x5fab 0x52bf 0x5216 0x56c3 0x4275 0x5c1c 0x6125 0x5c9d 0x5c31 0x5f23 0x4243 0x5cfc 0x6228 0x63b1 0x63ca 0x6251 0x3b9d 0x5d6b 0x61bf 0x69c0 0x6a3c 0x634c 0x35a5 0x5db3 0x6108 0x6c4e 0x6ddf 0x64b4 0x34a7 0x5e6c 0x5f72 0x6463 0x6eff 0x6e5d 0x3424 0x5f99 0x5d66 0x5944 0x6f9e 0x7af2 0x33ef 0x5e01 0x5cdd 0x572a 0x6ee4 0x7b64 0x33d0 0x520b 0x5c96 0x579a 0x6b64 0x74c5 0x33c3 0x475b 0x5c8b 0x5961 0x68dc 0x6f68 0x3431 0x4285 0x5eb5 0x62ce 0x67e1 0x6b96 0x350b 0x3f2c 0x625f 0x6c9c 0x6752 0x67e7 0x35aa 0x3de8 0x65c8 0x6eb5 0x66ae 0x64dc 0x362a 0x3a5d 0x698a 0x6fb2 0x6581 0x614d 0x3695 0x37d4 0x6ab6 0x6fe1 0x6646 0x6097 0x36e8 0x38e9 0x66b8 0x6f6e 0x6cbc 0x67ae 0x3730 0x3aa5 0x61e6 0x6e9a 0x727f 0x6f1b 0x3780 0x3ad2 0x6015 0x6a6b 0x72eb 0x7060 0x37d7 0x3a55 0x5f00 0x63df 0x72cf 0x70c6 0x37fa 0x3a15 0x5d88 0x61b0 0x7231 0x7197 0x37e9 0x3a6f 0x5a4c 0x60b6 0x6ef0 0x7362 0x37c2 0x3ad0 0x57d3 0x5f7a 0x6cdf 0x74c1 0x373b 0x3a8c 0x5a21 0x5d5b 0x6bbb 0x730c 0x3629 0x3a01 0x5d6b 0x5a1c 0x6848 0x6f08 0x35ae 0x3a03 0x5b4a 0x5211 0x63be 0x6af0 0x354f 0x39db 0x5584 0x51dc 0x64d2 0x6e31 0x3589 0x38c2 0x553d 0x5d05 0x727f 0x7bae 0x35e2 0x385a 0x4b49 0x5aca 0x64bd 0x6769 0x3545 0x392c 0x4f0b 0x5a6e 0x598d 0x6337 0x36c0 0x3a50 0x5198 0x55a8 0x5683 0x6026 0x381e 0x3dc7 0x52d4 0x551a 0x5a0d 0x6032 0x397e 0x42c4 0x5463 0x5dde 0x6a30 0x6bb4 0x38f9 0x4453 0x559b 0x5df3 0x68c9 0x7ad4 0x384c 0x42cc 0x4fde 0x5ad1 0x6e6c 0x7e5a 0x36b7 0x3e3d 0x44c9 0x6201 0x7267 0x8237 0x360e 0x37fa 0x3e15 0x6055 0x7680 0x74f7 0x360e 0x37fa 0x3e15 0x6055 0x7680 0x74f7 0x360e 0x37fa 0x3e15 0x6055 0x7680 0x74f7>;
				};

				qcom,pc-temp-y6-lut {
					qcom,lut-col-legend = <0xfffffff6 0x00 0x0a 0x19 0x28 0x32>;
					qcom,lut-row-legend = <0x2710 0x2648 0x2580 0x24b8 0x23f0 0x2328 0x2260 0x2198 0x20d0 0x2008 0x1f40 0x1e78 0x1db0 0x1ce8 0x1c20 0x1b58 0x1a90 0x19c8 0x1900 0x1838 0x1770 0x16a8 0x15e0 0x1518 0x1450 0x1388 0x12c0 0x11f8 0x1130 0x1068 0xfa0 0xed8 0xe10 0xd48 0xc80 0xbb8 0xaf0 0xa28 0x960 0x898 0x7d0 0x708 0x640 0x578 0x4b0 0x3e8 0x384 0x320 0x2bc 0x258 0x1f4 0x190 0x12c 0xc8 0x64 0x00>;
					qcom,lut-data = <0x1705 0x147d 0x13ba 0x1356 0x1341 0x133e 0x16f1 0x148a 0x13bc 0x1356 0x1341 0x133e 0x16dd 0x1492 0x13bc 0x1355 0x1341 0x133e 0x16cb 0x1497 0x13bc 0x1355 0x1341 0x133e 0x16bb 0x149a 0x13bc 0x1355 0x1342 0x133e 0x16af 0x149a 0x13bc 0x1355 0x1342 0x133e 0x16a8 0x1497 0x13bb 0x1356 0x1342 0x133f 0x16a2 0x1492 0x13ba 0x1356 0x1342 0x133f 0x1692 0x1490 0x13ba 0x1357 0x1343 0x133f 0x1675 0x148e 0x13bb 0x1358 0x1344 0x1340 0x1669 0x148e 0x13bd 0x1359 0x1344 0x1340 0x167a 0x149d 0x13be 0x135a 0x1345 0x1341 0x168d 0x14ad 0x13c0 0x135b 0x1346 0x1342 0x1663 0x14ab 0x13c9 0x135f 0x1347 0x1342 0x15e8 0x149e 0x13db 0x1364 0x1349 0x1343 0x15b8 0x148b 0x13df 0x1367 0x134b 0x1345 0x15b8 0x1468 0x13d3 0x1369 0x134c 0x1346 0x15b8 0x144a 0x13c3 0x136a 0x134e 0x1348 0x15b2 0x1444 0x13b8 0x136f 0x1354 0x134c 0x15a3 0x1441 0x13ae 0x1375 0x135a 0x1351 0x159a 0x143c 0x13a4 0x1373 0x1359 0x1350 0x1594 0x1434 0x139b 0x1361 0x134c 0x1347 0x1591 0x142d 0x1395 0x1354 0x1343 0x1340 0x1596 0x142b 0x1392 0x1351 0x1342 0x133f 0x15a4 0x1429 0x1391 0x134f 0x1341 0x133f 0x15b2 0x1427 0x1391 0x134f 0x1341 0x133e 0x15c0 0x1424 0x1391 0x134f 0x1341 0x133f 0x15d1 0x1422 0x1392 0x1350 0x1341 0x133f 0x15e7 0x1427 0x1393 0x1352 0x1342 0x133f 0x1600 0x1431 0x1395 0x1353 0x1343 0x1340 0x1619 0x143b 0x1395 0x1355 0x1344 0x1341 0x1631 0x1446 0x1396 0x1356 0x1346 0x1342 0x164a 0x1453 0x1397 0x1357 0x1347 0x1343 0x1665 0x1463 0x1398 0x1358 0x1349 0x1345 0x1682 0x1476 0x139a 0x1358 0x134a 0x1346 0x16a4 0x148c 0x139c 0x1357 0x1348 0x1345 0x16c9 0x14a5 0x139e 0x1354 0x1344 0x1341 0x16ef 0x14c3 0x13a1 0x1353 0x1342 0x133f 0x1715 0x14e5 0x13a6 0x1352 0x1341 0x133f 0x1739 0x150e 0x13ab 0x1352 0x1341 0x133f 0x1756 0x153e 0x13b2 0x1353 0x1342 0x133f 0x1771 0x1576 0x13bb 0x1354 0x1343 0x1340 0x1798 0x15b7 0x13c6 0x1355 0x1343 0x1340 0x17bc 0x1607 0x13d0 0x1356 0x1343 0x1340 0x17c0 0x1632 0x13d1 0x1355 0x1342 0x133e 0x17df 0x167b 0x13e6 0x135a 0x1344 0x1341 0x17fd 0x16bb 0x13fb 0x135d 0x1346 0x1342 0x182a 0x16f4 0x1415 0x1361 0x1348 0x1344 0x1854 0x172a 0x1433 0x1366 0x134b 0x1348 0x1883 0x1767 0x1453 0x136b 0x134c 0x1347 0x18b2 0x1789 0x1468 0x1368 0x1347 0x1343 0x18f4 0x17b5 0x1482 0x136b 0x1348 0x1344 0x194d 0x1803 0x14c4 0x1376 0x134c 0x1346 0x19f4 0x186a 0x152a 0x1385 0x1352 0x134a 0x19f4 0x186a 0x152a 0x1385 0x1352 0x134a 0x19f4 0x186a 0x152a 0x1385 0x1352 0x134a>;
				};
			};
